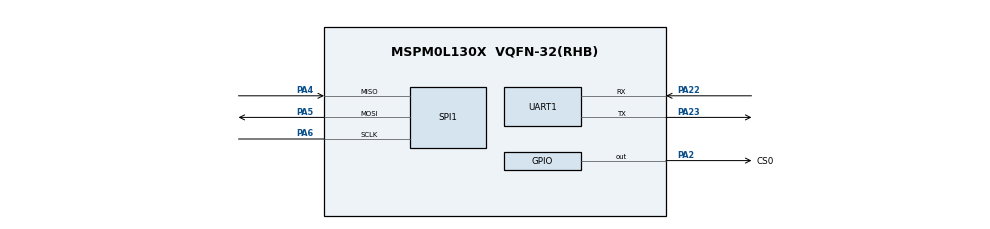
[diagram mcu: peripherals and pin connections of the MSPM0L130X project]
/**
 * @cliArgs --device "MSPM0L130X" --package "VQFN-32(RHB)" --part "Default" --product "mspm0_sdk@1.20.01.06"
 * @versions {"tool":"1.18.0+3266"}
 */

/**
 * Import the modules used in this configuration.
 */
const GPIO   = scripting.addModule("/ti/driverlib/GPIO", {}, false);
const GPIO1  = GPIO.addInstance();
const GPIO2  = GPIO.addInstance();
const SPI    = scripting.addModule("/ti/driverlib/SPI", {}, false);
const SPI1   = SPI.addInstance();
const SYSCTL = scripting.addModule("/ti/driverlib/SYSCTL");
const UART   = scripting.addModule("/ti/driverlib/UART", {}, false);
const UART1  = UART.addInstance();

/**
 * Write custom configuration values to the imported modules.
 */
GPIO1.$name                         = "GPIO_LEDS";
GPIO1.port                          = "PORTA";
GPIO1.associatedPins[0].$name       = "USER_LED_1";
GPIO1.associatedPins[0].assignedPin = "0";

const Board = scripting.addModule("/ti/driverlib/Board", {}, false);

GPIO2.$name                          = "SPI0";
GPIO2.associatedPins[0].$name        = "CS0";
GPIO2.associatedPins[0].initialValue = "SET";
GPIO2.associatedPins[0].pin.$assign  = "PA2";

SPI1.$name                      = "SPI_0";
SPI1.enableDMAEvent1            = false;
SPI1.enableDMAEvent2            = false;
SPI1.phase                      = "1";
SPI1.frameFormat                = "MOTO3";
SPI1.polarity                   = "1";
SPI1.delayedSampling            = 1;
SPI1.targetBitRate              = 500000;
SPI1.peripheral.$assign         = "SPI0";
SPI1.peripheral.sclkPin.$assign = "PA6";
SPI1.peripheral.mosiPin.$assign = "PA5";
SPI1.peripheral.misoPin.$assign = "PA4";
SPI1.sclkPinConfig.$name        = "ti_driverlib_gpio_GPIOPinGeneric2";
SPI1.mosiPinConfig.$name        = "ti_driverlib_gpio_GPIOPinGeneric3";
SPI1.misoPinConfig.$name        = "ti_driverlib_gpio_GPIOPinGeneric4";

SYSCTL.clockTreeEn = true;

UART1.$name                    = "UART_0";
UART1.targetBaudRate           = 115200;
UART1.rxFifoThreshold          = "DL_UART_RX_FIFO_LEVEL_ONE_ENTRY";
UART1.enableDMARX              = false;
UART1.enableDMATX              = false;
UART1.enabledInterrupts        = ["RX"];
UART1.peripheral.$assign       = "UART0";
UART1.peripheral.rxPin.$assign = "PA22";
UART1.peripheral.txPin.$assign = "PA23";
UART1.txPinConfig.$name        = "ti_driverlib_gpio_GPIOPinGeneric0";
UART1.rxPinConfig.$name        = "ti_driverlib_gpio_GPIOPinGeneric1";

/**
 * Pinmux solution for unlocked pins/peripherals. This ensures that minor changes to the automatic solver in a future
 * version of the tool will not impact the pinmux you originally saw.  These lines can be completely deleted in order to
 * re-solve from scratch.
 */
GPIO1.associatedPins[0].pin.$suggestSolution = "PA0";
Board.peripheral.$suggestSolution            = "DEBUGSS";
Board.peripheral.swclkPin.$suggestSolution   = "PA20";
Board.peripheral.swdioPin.$suggestSolution   = "PA19";
